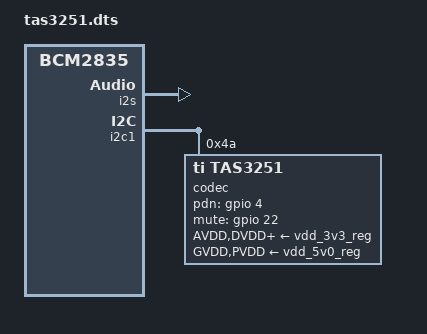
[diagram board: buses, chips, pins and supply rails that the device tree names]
// dtc -I dts -O dtb -o /boot/overlays/tas3251.dtbo tas3251.dts
// Definitions for TAS3251 simple card
/dts-v1/;
/plugin/;

/ {
	compatible = "brcm,bcm2835";

	fragment@0 {
		target = <&i2s>;
		__overlay__ {
			status = "okay";
		};
	};

	fragment@1 {
		target = <&i2c1>;
		__overlay__ {
			#address-cells = <1>;
			#size-cells = <0>;
			status = "okay";

			codec: tas3251@4a {
				#sound-dai-cells = <0>;
				compatible = "ti,tas3251";
//				compatible = "ti,pcm5122";
				reg = <0x4a>;
				firmware = "default";
				AVDD-supply = <&vdd_3v3_reg>;
				DVDD-supply = <&vdd_3v3_reg>;
				CPVDD-supply = <&vdd_3v3_reg>;
				GVDD-supply = <&vdd_5v0_reg>;
				PVDD-supply = <&vdd_5v0_reg>;
				pdn-gpios = <&gpio 4 0>;
				mute-gpios = <&gpio 22 0>;

				status = "okay";
			};
		};
	};

    fragment@2 {
        target = <&sound>;
        __overlay__ {
            status = "okay";
            compatible = "simple-audio-card";
            label = "AmpliMuseAmp 2x175W";
            simple-audio-card,dai-link {
                /* DAC */
                format = "i2s";
                bitclock-master = <&dailink_master>;
                frame-master = <&dailink_master>;
                dailink_master: cpu {
                        sound-dai = <&i2s>;
                        dai-tdm-slot-num = <2>;
                        dai-tdm-slot-width = <32>;
                };
            codec {
                    sound-dai = <&codec>;
            };
        };
    };
  };
	__overrides__ {
		firmware = <&codec>,"firmware";
		i2creg = <&codec>,"reg:<>";
	};
};
